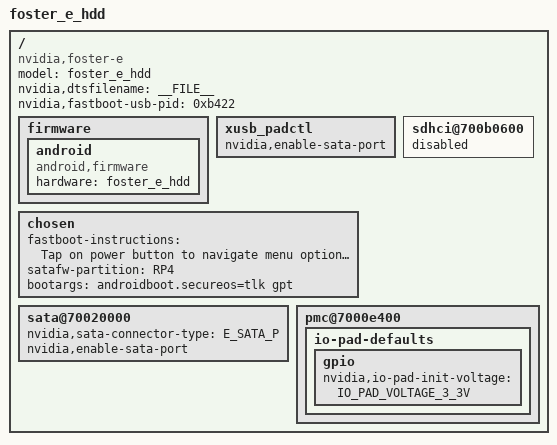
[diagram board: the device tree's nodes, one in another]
/*
 * arch/arm64/boot/dts/tegra210-foster-e-hdd-p2530-0932-e00-00.dts
 *
 * Copyright (c) 2014-2017, NVIDIA CORPORATION.  All rights reserved.
 *
 * This program is free software; you can redistribute it and/or modify
 * it under the terms of the GNU General Public License as published by
 * the Free Software Foundation; version 2 of the License.
 *
 * This program is distributed in the hope that it will be useful, but WITHOUT
 * ANY WARRANTY; without even the implied warranty of MERCHANTABILITY or
 * FITNESS FOR A PARTICULAR PURPOSE.  See the GNU General Public License for
 * more details.
 *
 * You should have received a copy of the GNU General Public License along
 * with this program; if not, write to the Free Software Foundation, Inc.,
 * 51 Franklin Street, Fifth Floor, Boston, MA  02110-1301, USA.
 *
 */
#include "tegra210-foster-e-p2530-common.dtsi"
#include "tegra210-platforms/tegra210-foster-e-pinmux-p2530-0930-e00.dtsi"
#include "tegra210-platforms/tegra210-foster-e-extcon-p2530-0930-e01.dtsi"
#include "tegra210-platforms/tegra210-loki-e-emc-a01.dtsi"
#include "tegra210-platforms/tegra210-foster-powermon-p2530-0930-e01.dtsi"

/ {
	model = "foster_e_hdd";
	compatible = "nvidia,foster-e", "nvidia,tegra210";
	nvidia,dtsfilename = __FILE__;
	nvidia,fastboot-usb-pid = <0xb422>;

	firmware {
		android {
			compatible = "android,firmware";
			hardware = "foster_e_hdd";
		};
	};

	xusb_padctl {
		nvidia,enable-sata-port;
	};

	chosen {
		fastboot-instructions = "Tap on power button to navigate menu options.\nHold down power button for 2 sec and release for selecting an option.\nOem unlock may take upto 2 hours.\n";
		satafw-partition = "RP4";
		bootargs = "androidboot.secureos=tlk gpt";
	};

	sata@70020000 {
		status = "okay";
		nvidia,sata-connector-type=<E_SATA_P>;
		nvidia,enable-sata-port;
	};

	sdhci@700b0600 {
		status="disabled";
	};

	pmc@7000e400 {
		io-pad-defaults {
			gpio {
				nvidia,io-pad-init-voltage = <IO_PAD_VOLTAGE_3_3V>;
			};
		};
	};
};
